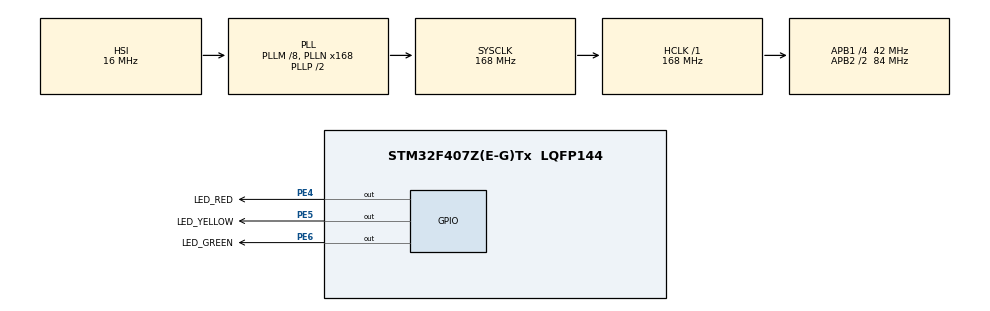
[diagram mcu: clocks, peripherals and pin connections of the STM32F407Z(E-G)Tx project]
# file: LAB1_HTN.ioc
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Mcu.Family=STM32F4
Mcu.Name=STM32F407Z(E-G)Tx
Mcu.Package=LQFP144
NVIC.PriorityGroup=NVIC_PRIORITYGROUP_4
PA13.Mode=Serial_Wire
PA13.Signal=SYS_JTMS-SWDIO
PA14.Mode=Serial_Wire
PA14.Signal=SYS_JTCK-SWCLK
PE4.GPIO_Label=LED_RED
PE4.GPIO_PuPd=GPIO_PULLUP
PE4.Signal=GPIO_Output
PE5.GPIO_Label=LED_YELLOW
PE5.GPIO_PuPd=GPIO_PULLUP
PE5.Signal=GPIO_Output
PE6.GPIO_Label=LED_GREEN
PE6.GPIO_PuPd=GPIO_PULLUP
PE6.Signal=GPIO_Output
PH0-OSC_IN.Mode=HSE-External-Oscillator
PH0-OSC_IN.Signal=RCC_OSC_IN
PH1-OSC_OUT.Mode=HSE-External-Oscillator
PH1-OSC_OUT.Signal=RCC_OSC_OUT
ProjectManager.HeapSize=0x200
ProjectManager.StackSize=0x400
ProjectManager.TargetToolchain=STM32CubeIDE
RCC.48MHZClocksFreq_Value=84000000
RCC.AHBFreq_Value=168000000
RCC.APB1CLKDivider=RCC_HCLK_DIV4
RCC.APB1Freq_Value=42000000
RCC.APB1TimFreq_Value=84000000
RCC.APB2CLKDivider=RCC_HCLK_DIV2
RCC.APB2Freq_Value=84000000
RCC.APB2TimFreq_Value=168000000
RCC.CortexFreq_Value=168000000
RCC.HCLKFreq_Value=168000000
RCC.HSE_VALUE=8000000
RCC.HSI_VALUE=16000000
RCC.LSE_VALUE=32768
RCC.PLLM=8
RCC.PLLN=168
RCC.SYSCLKFreq_VALUE=168000000
RCC.SYSCLKSource=RCC_SYSCLKSOURCE_PLLCLK
RCC.VCOOutputFreq_Value=336000000
board=custom

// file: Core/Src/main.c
/* USER CODE BEGIN Header */
/**
  ******************************************************************************
  * @file           : main.c
  * @brief          : Main program body
  ******************************************************************************
  * @attention
  *
  * Copyright (c) 2024 STMicroelectronics.
  * All rights reserved.
  *
  * This software is licensed under terms that can be found in the LICENSE file
  * in the root directory of this software component.
  * If no LICENSE file comes with this software, it is provided AS-IS.
  *
  ******************************************************************************
  */
/* USER CODE END Header */
#include "main.h"

void SystemClock_Config(void);
static void MX_GPIO_Init(void);

int main(void)
{

  /* MCU Configuration--------------------------------------------------------*/

  /* Reset of all peripherals, Initializes the Flash interface and the Systick. */
  HAL_Init();

  /* Configure the system clock */
  SystemClock_Config();

  /* Initialize all configured peripherals */
  MX_GPIO_Init();
  /* USER CODE BEGIN 2 */
  int count = 9;

  /* USER CODE END 2 */

  /* Infinite loop */
  /* USER CODE BEGIN WHILE */
  while (1)
  {
	  if(count == 9){
		  HAL_GPIO_WritePin(LED_RED_GPIO_Port, LED_RED_Pin, 1);
		  HAL_GPIO_WritePin(LED_YELLOW_GPIO_Port, LED_YELLOW_Pin, 0);
		  HAL_GPIO_WritePin(LED_GREEN_GPIO_Port, LED_GREEN_Pin, 0);

	  }
	  else if(count == 4)
	  {
		  HAL_GPIO_WritePin(LED_RED_GPIO_Port, LED_RED_Pin, 0);
		  HAL_GPIO_WritePin(LED_YELLOW_GPIO_Port, LED_YELLOW_Pin, 0);
		  HAL_GPIO_WritePin(LED_GREEN_GPIO_Port, LED_GREEN_Pin, 1);
	  }
	  else if(count == 1)
	  {
		  HAL_GPIO_WritePin(LED_RED_GPIO_Port, LED_RED_Pin, 0);
		  HAL_GPIO_WritePin(LED_YELLOW_GPIO_Port, LED_YELLOW_Pin, 1);
		  HAL_GPIO_WritePin(LED_GREEN_GPIO_Port, LED_GREEN_Pin, 0);
	  }
	  count--;
	  if(count == 0)
	  {
		  count = 9;
	  }
//	  HAL_GPIO_WritePin(LED_RED_GPIO_Port, LED_RED_Pin, 1);
//	  HAL_GPIO_WritePin(LED_GREEN_GPIO_Port, LED_GREEN_Pin, 1);
//	  HAL_GPIO_WritePin(LED_YELLOW_GPIO_Port, LED_YELLOW_Pin, 1);

	  HAL_Delay(1000);
    /* USER CODE END WHILE */

  }
}

void SystemClock_Config(void)
{
  RCC_OscInitTypeDef RCC_OscInitStruct = {0};
  RCC_ClkInitTypeDef RCC_ClkInitStruct = {0};

  /** Configure the main internal regulator output voltage
  */
  __HAL_RCC_PWR_CLK_ENABLE();
  __HAL_PWR_VOLTAGESCALING_CONFIG(PWR_REGULATOR_VOLTAGE_SCALE1);

  /** Initializes the RCC Oscillators according to the specified parameters
  * in the RCC_OscInitTypeDef structure.
  */
  RCC_OscInitStruct.OscillatorType = RCC_OSCILLATORTYPE_HSI;
  RCC_OscInitStruct.HSIState = RCC_HSI_ON;
  RCC_OscInitStruct.HSICalibrationValue = RCC_HSICALIBRATION_DEFAULT;
  RCC_OscInitStruct.PLL.PLLState = RCC_PLL_ON;
  RCC_OscInitStruct.PLL.PLLSource = RCC_PLLSOURCE_HSI;
  RCC_OscInitStruct.PLL.PLLM = 8;
  RCC_OscInitStruct.PLL.PLLN = 168;
  RCC_OscInitStruct.PLL.PLLP = RCC_PLLP_DIV2;
  RCC_OscInitStruct.PLL.PLLQ = 4;
  if (HAL_RCC_OscConfig(&RCC_OscInitStruct) != HAL_OK)
  {
    Error_Handler();
  }

  /** Initializes the CPU, AHB and APB buses clocks
  */
  RCC_ClkInitStruct.ClockType = RCC_CLOCKTYPE_HCLK|RCC_CLOCKTYPE_SYSCLK
                              |RCC_CLOCKTYPE_PCLK1|RCC_CLOCKTYPE_PCLK2;
  RCC_ClkInitStruct.SYSCLKSource = RCC_SYSCLKSOURCE_PLLCLK;
  RCC_ClkInitStruct.AHBCLKDivider = RCC_SYSCLK_DIV1;
  RCC_ClkInitStruct.APB1CLKDivider = RCC_HCLK_DIV4;
  RCC_ClkInitStruct.APB2CLKDivider = RCC_HCLK_DIV2;

  if (HAL_RCC_ClockConfig(&RCC_ClkInitStruct, FLASH_LATENCY_5) != HAL_OK)
  {
    Error_Handler();
  }
}

static void MX_GPIO_Init(void)
{
  GPIO_InitTypeDef GPIO_InitStruct = {0};

  /* GPIO Ports Clock Enable */
  __HAL_RCC_GPIOE_CLK_ENABLE();
  __HAL_RCC_GPIOH_CLK_ENABLE();
  __HAL_RCC_GPIOA_CLK_ENABLE();

  /*Configure GPIO pin Output Level */
  HAL_GPIO_WritePin(GPIOE, LED_RED_Pin|LED_YELLOW_Pin|LED_GREEN_Pin, GPIO_PIN_RESET);

  /*Configure GPIO pins : LED_RED_Pin LED_YELLOW_Pin LED_GREEN_Pin */
  GPIO_InitStruct.Pin = LED_RED_Pin|LED_YELLOW_Pin|LED_GREEN_Pin;
  GPIO_InitStruct.Mode = GPIO_MODE_OUTPUT_PP;
  GPIO_InitStruct.Pull = GPIO_PULLUP;
  GPIO_InitStruct.Speed = GPIO_SPEED_FREQ_LOW;
  HAL_GPIO_Init(GPIOE, &GPIO_InitStruct);

}

void Error_Handler(void)
{
  __disable_irq();
  while (1)
  {
  }
}
